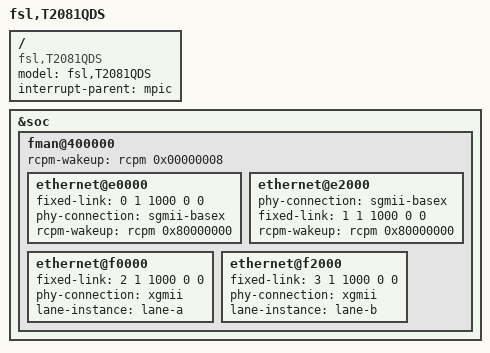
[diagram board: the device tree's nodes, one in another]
/*
 * T2080PCIe-RDB Board Device Tree Source
 *
 * Copyright 2014 Freescale Semiconductor Inc.
 *
 * Redistribution and use in source and binary forms, with or without
 * modification, are permitted provided that the following conditions are met:
 *     * Redistributions of source code must retain the above copyright
 *	 notice, this list of conditions and the following disclaimer.
 *     * Redistributions in binary form must reproduce the above copyright
 *	 notice, this list of conditions and the following disclaimer in the
 *	 documentation and/or other materials provided with the distribution.
 *     * Neither the name of Freescale Semiconductor nor the
 *	 names of its contributors may be used to endorse or promote products
 *	 derived from this software without specific prior written permission.
 *
 *
 * ALTERNATIVELY, this software may be distributed under the terms of the
 * GNU General Public License ("GPL") as published by the Free Software
 * Foundation, either version 2 of that License or (at your option) any
 * later version.
 *
 * THIS SOFTWARE IS PROVIDED BY Freescale Semiconductor "AS IS" AND ANY
 * EXPRESS OR IMPLIED WARRANTIES, INCLUDING, BUT NOT LIMITED TO, THE IMPLIED
 * WARRANTIES OF MERCHANTABILITY AND FITNESS FOR A PARTICULAR PURPOSE ARE
 * DISCLAIMED. IN NO EVENT SHALL Freescale Semiconductor BE LIABLE FOR ANY
 * DIRECT, INDIRECT, INCIDENTAL, SPECIAL, EXEMPLARY, OR CONSEQUENTIAL DAMAGES
 * (INCLUDING, BUT NOT LIMITED TO, PROCUREMENT OF SUBSTITUTE GOODS OR SERVICES;
 * LOSS OF USE, DATA, OR PROFITS; OR BUSINESS INTERRUPTION) HOWEVER CAUSED AND
 * ON ANY THEORY OF LIABILITY, WHETHER IN CONTRACT, STRICT LIABILITY, OR TORT
 * (INCLUDING NEGLIGENCE OR OTHERWISE) ARISING IN ANY WAY OUT OF THE USE OF THIS
 * SOFTWARE, EVEN IF ADVISED OF THE POSSIBILITY OF SUCH DAMAGE.
 */

/include/ "ifc14xx-pre.dtsi"
/include/ "ifc14xx.dtsi"

/ {
	model = "fsl,T2081QDS";
	compatible = "fsl,T2081QDS";
	#address-cells = <2>;
	#size-cells = <2>;
	interrupt-parent = <&mpic>;
};

&soc {
	fman@400000 {
                rcpm-wakeup = <&rcpm 0x00000008>;
		ethernet@e0000 { /* 10GEC3 */
	                fixed-link = <0 1 1000 0 0>;
			phy-connection = "sgmii-basex";
                        rcpm-wakeup = <&rcpm 0x80000000>;
		};

		ethernet@e2000 { /* 10GEC4 */
			phy-connection = "sgmii-basex";
	                fixed-link = <1 1 1000 0 0>;
                        rcpm-wakeup = <&rcpm 0x80000000>;
		};

		ethernet@f0000 { /* DTSEC9/10GEC1 */
			fixed-link = <2 1 1000 0 0>;
			phy-connection = "xgmii";
			lane-instance = "lane-a";
		};

		ethernet@f2000 { /* DTSEC10/10GEC2 */
			fixed-link = <3 1 1000 0 0>;
			phy-connection = "xgmii";
			lane-instance = "lane-b";
		};
	};
};

/include/ "t2081si-post.dtsi"
